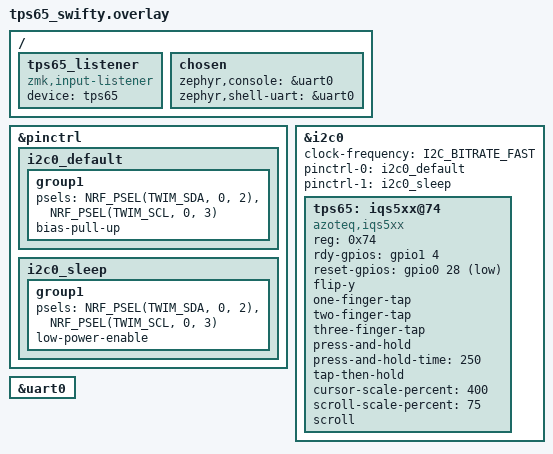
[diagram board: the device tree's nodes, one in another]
/*
 * Azoteq IQS5xx (TPS65) touchpad add-on for the Swifty keyboard
 * running on nice_nano (nRF52840). Pads are on the right-half PCB.
 *
 * SoC pin assignment:
 *   P0.02 -> TPS65 SDA
 *   P0.03 -> TPS65 SCL
 *   P1.04 -> TPS65 RDY    (active-high, open-drain; pull-up applied)
 *   P0.28 -> TPS65 NRST   (active-low; optional)
 *   3V3   -> TPS65 VDD
 *   GND   -> TPS65 GND
 *
 * Reuses i2c0 with custom pinctrl so the default SDA/SCL pin
 * defaults are not touched.
 */

&pinctrl {
    i2c0_default: i2c0_default {
        group1 {
            psels = <NRF_PSEL(TWIM_SDA, 0, 2)>,
                    <NRF_PSEL(TWIM_SCL, 0, 3)>;
            bias-pull-up;
        };
    };

    i2c0_sleep: i2c0_sleep {
        group1 {
            psels = <NRF_PSEL(TWIM_SDA, 0, 2)>,
                    <NRF_PSEL(TWIM_SCL, 0, 3)>;
            low-power-enable;
        };
    };

};

&i2c0 {
    status = "okay";
    clock-frequency = <I2C_BITRATE_FAST>;
    pinctrl-0 = <&i2c0_default>;
    pinctrl-1 = <&i2c0_sleep>;
    pinctrl-names = "default", "sleep";

    tps65: iqs5xx@74 {
        status = "okay";
        compatible = "azoteq,iqs5xx";
        reg = <0x74>;

        rdy-gpios   = <&gpio1 4 GPIO_ACTIVE_HIGH>;
        reset-gpios = <&gpio0 28 GPIO_ACTIVE_LOW>;

        /* Invert the cursor's vertical axis, applied by the chip itself. This
         * only works because the driver re-applies the configuration after a
         * chip reset - without that, the axis settings silently reverted to the
         * chip's factory defaults, which look like a rotated cursor. */
        flip-y;

        one-finger-tap;
        two-finger-tap;
        three-finger-tap;
        press-and-hold;
        /* Held for this long IN ADDITION to the chip's own tap time, so keep it
         * comfortably above it - too short and a stationary press is classified
         * as a tap instead of a hold. */
        press-and-hold-time = <250>;
        /* Tap, then touch + drag within the 200ms window: engages the same
         * drag-lock with no hold-time wait. Arms only off a clean one-finger tap
         * and cancels on multi-finger activity, so double-clicks pass through. */
        tap-then-hold;

        /* Cursor speed, in-driver: 100 = chip default, 400 = 4x. Scroll is not
         * scaled from it (the driver only couples scroll when SLOWING the
         * cursor), so scrolling stays at the chip's own rate - one wheel tick
         * per 32 counts. */
        cursor-scale-percent = <400>;

        /* Wheel rate, independent of the cursor: 100 = the chip's own rate,
         * 75 = a quarter slower, 50 = half. */
        scroll-scale-percent = <75>;

        scroll;
    };
};

/ {
    /* Orientation and speed are both handled by the driver now: flip-y and
     * cursor-scale-percent on the tps65 node above. No input processors. */

    tps65_listener: tps65_listener {
        compatible = "zmk,input-listener";
        device = <&tps65>;
    };

    chosen {
        zephyr,console = &uart0;
        zephyr,shell-uart = &uart0;
    };
};

/* UART debug log on TX=P0.06, RX=P0.08 (nice_nano's uart0_default
 * pinctrl already maps to these pads). */
&uart0 {
    status = "okay";
};


